# Z32F0642 register map
Vendor: Zilog, Inc.; File version: 1.0.0
ARM 32-bit Cortex-M0 Microcontroller based device.
CPU: CM0 r1p0, little endian, no MPU, no FPU, 2 interrupt priority bits
Registers are 32-bit, read-write, reset 0x0 unless marked. A register's access mark holds for its fields unless they carry their own. Offsets are from the block's base; lines under a group give offsets from that group; [hi:lo] are bit positions; {n}, {i} and the like mark numbered series; 'fields as' and 'values as' point back to an identical list; <NAME> marks a mode.

## Memory map
0x40000000 SCU size 0x100 — SYSTEM CONTROL UNIT
0x40000100 FM size 0x100 — FLASH MEMORY CONTROLLER
0x40000200 WDT size 0x100 — WATCH-DOG TIMER
0x40000500 DIV64 size 0x100 — DIVIDER
0x40000600 FRT size 0x100 — Free-run Timer
0x40001000 PCA size 0x100 — PORT CONTROL UNIT
0x40001100 PCB size 0x100
0x40001200 PCC size 0x100
0x40001300 PCD size 0x100
0x40001FF0 PORTEN size 0x10 — Port Control Mode Enable Register
0x40002000 PA size 0x100 — GENERAL PURPOSE I/O
0x40002100 PB size 0x100
0x40002200 PC size 0x100
0x40002300 PD size 0x100
0x40003000 T0 size 0x20 — 16-BIT TIMER
0x40003020 T1 size 0x20
0x40003040 T2 size 0x20
0x40003060 T3 size 0x20
0x40004000 MP size 0x1000 — MOTOR PULSE-WIDTH-MODULATOR
0x40008000 U0 size 0x100 — UNIVERSAL ASYNCHRONOUS RECEIVER/TRANSMITTER
0x40008100 U1 size 0x100
0x40009000 SP size 0x100 — SERIAL PERIPHERAL INTERFACE
0x4000A000 IC size 0x100 — I2C Interface
0x4000B000 AD size 0x100 — 12-BIT A/D CONVERTER

## Interrupts
0 LVDDETECT (SCU)
1 SYSCLKFAIL (SCU)
2 MOSCFAIL (SCU)
3 SOSCFAIL (SCU)
4 WDT
5 TIMER0 (T0)
6 TIMER1 (T1)
7 TIMER2 (T2)
8 TIMER3 (T3)
9 FRT
10 GPIOAE (PCA)
11 GPIOAO (PCA)
12 GPIOBE (PCB)
13 GPIOBO (PCB)
14 GPIOCE (PCC)
15 GPIOCO (PCC)
16 GPIODE (PCD)
17 GPIODO (PCD)
18 MPWM (MP)
19 MPWMPROT (MP)
20 MPWMOVV (MP)
21 I2C (IC)
22 SPI (SP)
23 UART0 (U0)
24 UART1 (U1)
25 ADC (AD)

## PCA — PORT CONTROL UNIT
Base 0x40001000
Same registers: PCB 0x40001100, PCC 0x40001200, PCD 0x40001300
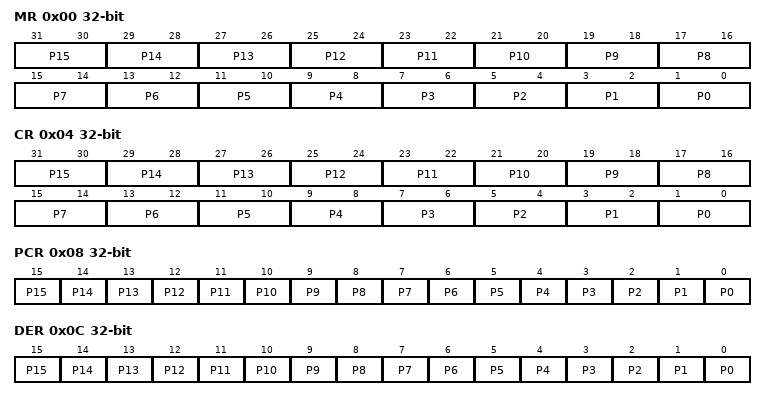
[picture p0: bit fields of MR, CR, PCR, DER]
0x00 MR — PORT n Pin MUX Register
  [2n+1:2n] P{n} (n=0..15) — P{n} MUX SEL
0x04 CR — PORT n Pin Control Register
  [2n+1:2n] P{n} (n=0..15) — P{n} control SEL
0x08 PCR — PORT n Pull-up Resistor Control Register
  [n] P{n} (n=0..15) — P{n} pull-up enable
0x0C DER — PORT n Debounce Enable Register
  [n] P{n} (n=0..15) — P{n} Debounce enable
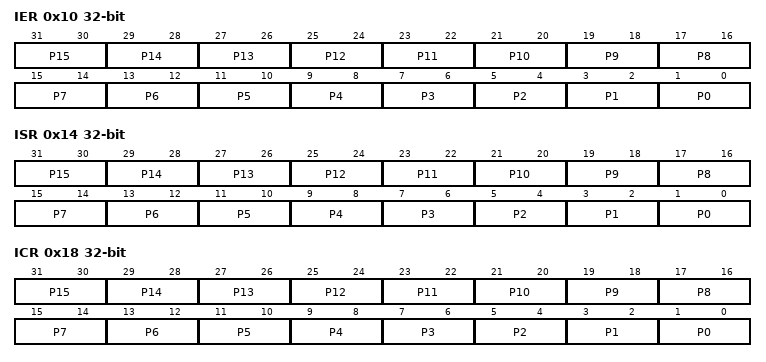
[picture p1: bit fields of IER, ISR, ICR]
0x10 IER — PORT n Interrupt Enable Register
  [2n+1:2n] P{n} (n=0..15) — P{n} interrupt enable
0x14 ISR — PORT n Interrupt Status Register
  [2n+1:2n] P{n} (n=0..15) — P{n} interrupt status
0x18 ICR — PORT n Interrupt Control Register
  [2n+1:2n] P{n} (n=0..15) — P{n} interrupt control

## PORTEN — Port Control Mode Enable Register
Base 0x40001FF0
0x00 EN (reset mask 0xFFFF) — Port Access Enable 0x15->0x51

## PA — GENERAL PURPOSE I/O
Base 0x40002000
Same registers: PB 0x40002100, PC 0x40002200, PD 0x40002300
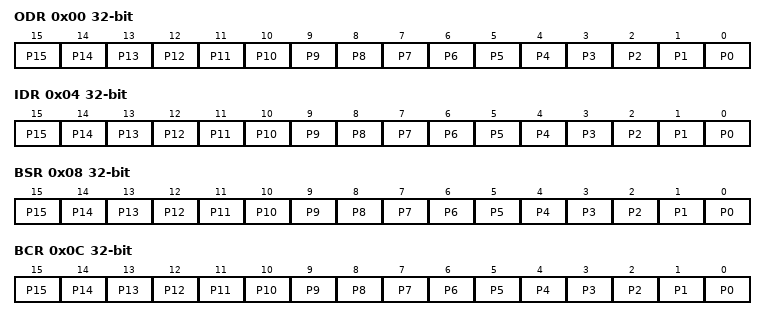
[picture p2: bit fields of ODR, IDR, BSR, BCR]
0x00 ODR — PORT n Output Data Register
  [n] P{n} (n=0..15) — P{n} Output level
0x04 IDR ro — PORT n Input Data Register
  [n] P{n} (n=0..15) — P{n} Input level
0x08 BSR — PORT n Bit Set Register
  [n] P{n} (n=0..15) — P{n} bit set
0x0C BCR wo — PORT n Bit Clear Register
  [n] P{n} (n=0..15) — P{n} bit clear

## FM — FLASH MEMORY CONTROLLER
Base 0x40000100
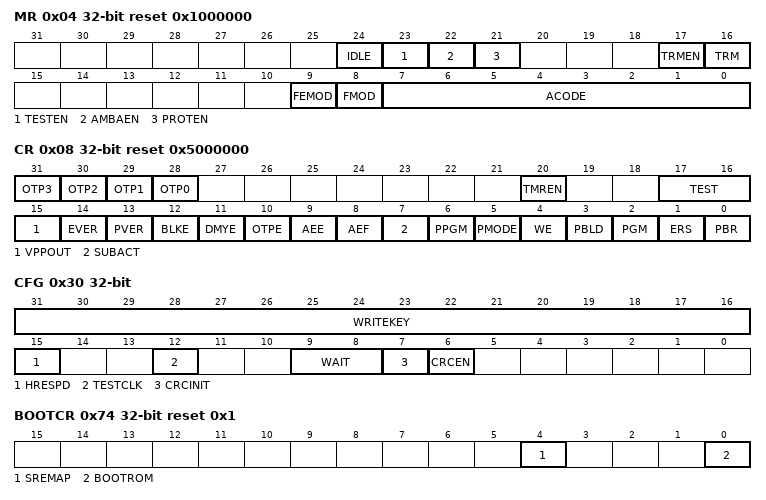
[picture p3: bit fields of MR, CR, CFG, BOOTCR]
0x04 MR reset 0x1000000 — Flash Memory Mode Register
  [24] IDLE ro — Idle mode status
  [23] TESTEN ro — Flash test
  [22] AMBAEN ro — AMBA mode enable
  [21] PROTEN ro — Flash protection
  [17] TRMEN ro — Trim Mode entry status
  [16] TRM ro — Trim Mode status
  [9] FEMOD ro — Flash Mode entry status
  [8] FMOD ro — Flash Mode status
  [7:0] ACODE — Flash Mode/Trim Mode
0x08 CR reset 0x5000000 — Flash Memory Control Register
  [n+28] OTP{n} (n=0..3)
  [20] TMREN — program timer enable
  [17:16] TEST
  [15] VPPOUT — Charge pump Vpp Output
  [14] EVER — Erase verify Mode
  [13] PVER — Program verify mode
  [12] BLKE — 128page write enable for full chip writing to save program time
  [11] DMYE — DUMMY Area enable
  [10] OTPE — OTP area a,b,c,d enable
  [9] AEE
  [8] AEF — All Erase
  [7] SUBACT
  [6] PPGM
  [5] PMODE — Pmode Enable
  [4] WE — write Enable
  [3] PBLD — page buffer load
  [2] PGM
  [1] ERS — program mode/erase mode Enable
  [0] PBR — page buffer reset
0x0C AR — Flash Memory Address Register
  [14:0] FADDR — 16K words address
0x10 DR — Flash Memory Data Register
  [31:0] FDATA — Flash PGM data
0x14 TMR reset 0xBB (reset mask 0xFFFF) — Flash Memory Timer Register
  [17:0] TMR — Erase/PGM timer
0x18 DIRTY wo — Flash Memory Dirty Register
  [31:0] FDIRTY — Write any value to clear the Cache line fill
0x1C TICK — Flash Memory Tick Timer register
  [31:0] FTICK — TICK
0x20 CRC — Flash Memory CRC value register
  [15:0] CRC — CRC16 Value
0x30 CFG — Flash Memory CONFIG value register
  [31:16] WRITEKEY
  [15] HRESPD
  [12] TESTCLK
  [9:8] WAIT
  [7] CRCINIT
  [6] CRCEN — CRC16 Enable
0x40 HWID ro — Flash Hardware ID Register
  [31:0] FHWID — FHWID Value
0x74 BOOTCR reset 0x1 — Boot ROM Remap Clear Register
  [4] SREMAP — SRAM remap enable
  [0] BOOTROM — Boot mode
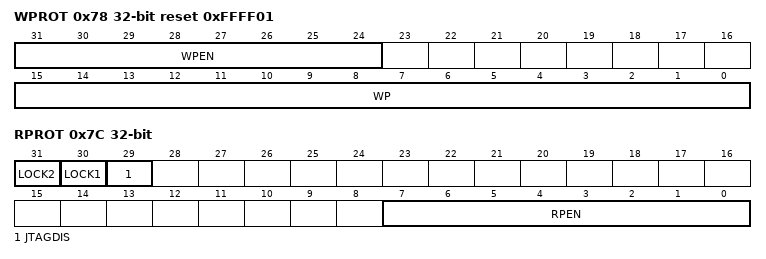
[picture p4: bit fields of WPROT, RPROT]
0x78 WPROT reset 0xFFFF01 — Flash Memory Write Protection Register
  [31:24] WPEN — WP access enable
  [15:0] WP — Sector protect
0x7C RPROT — Flash Memory Read Protection Register
  [31] LOCK2 ro — Read Protection Level 2 State Flag
  [30] LOCK1 ro — Read Protection Level 1 State Flag
  [29] JTAGDIS ro — JTAG Disable State Flag
  [7:0] RPEN — Read Protection Enable

## Licence text in the file
THIS SOFTWARE IS PROVIDED "AS IS". NO WARRANTIES, WHETHER EXPRESS, IMPLIED. OR STATUTORY, INCLUDING, BUT NOT LIMITED TO, IMPLIED WARRANTIES OF. MERCHANTABILITY AND FITNESS FOR A PARTICULAR PURPOSE APPLY TO THIS SOFTWARE. ARM SHALL NOT, IN ANY CIRCUMSTANCES, BE LIABLE FOR SPECIAL, INCIDENTAL, OR. CONSEQUENTIAL DAMAGES, FOR ANY REASON WHATSOEVER.
